# Port_E_4 register map
Vendor: Texas Instruments
Peripheral module from a debugger description file (folder msp430).
Registers are 16-bit, read-write, reset 0x0 unless marked. A register's access mark holds for its fields unless they carry their own. Offsets are as the file gives them; lines under a group give offsets from that group; [hi:lo] are bit positions; {n}, {i} and the like mark numbered series; 'fields as' and 'values as' point back to an identical list; <NAME> marks a mode.

## Port_E
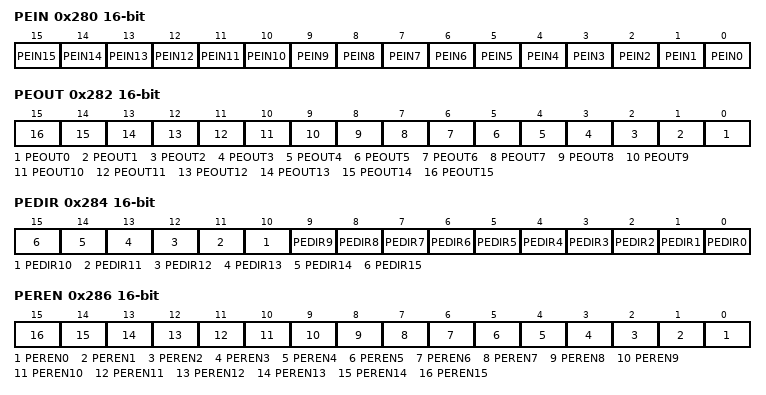
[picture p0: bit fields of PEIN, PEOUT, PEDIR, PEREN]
0x280 PEIN — Port E Input
  [n] PEIN{n} (n=0..15)
0x282 PEOUT — Port E Output
  [n] PEOUT{n} (n=0..15)
0x284 PEDIR — Port E Direction
  [n] PEDIR{n} (n=0..15)
0x286 PEREN — Port E Resistor Enable
  [n] PEREN{n} (n=0..15)
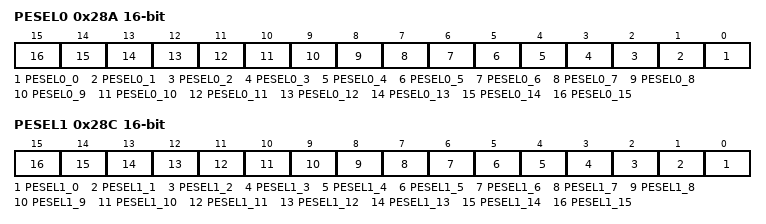
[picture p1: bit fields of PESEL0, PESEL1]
0x28A PESEL0 — Port E Selection 0
  [n] PESEL0_{n} (n=0..15)
0x28C PESEL1 — Port E Selection 1
  [n] PESEL1_{n} (n=0..15)
0x296 PESELC access not given reset not defined — Port E Complement Selection
